# H5 register map
Vendor: Allwinner; Series: H5; File version: 0.1
CPU: 0, little endian, MPU, no FPU, 0 interrupt priority bits
Registers are 32-bit, read-write, reset 0x0 unless marked. A register's access mark holds for its fields unless they carry their own. Offsets are from the block's base; [hi:lo] are bit positions; {n}, {i} and the like mark numbered series.

## SPC
Base 0x01C23400
0x04 SPC_DECPORT0_STA_REG — SPC Decode Port0 Status Register
  [7:0] STA_DEC_PROT0_OUT ro — Shows the status of the decode protection output 0: Decode region corresponding to the bit is secure 1: Decode region corresponding to the bit is non-secure. There is one bit of the register for each protection output (See the SPC Configuration Table in Table 4-7 for detail).
{0x8+0xC*i} SPC_DECPORT{i}_SET_REG (i=0..2) — SPC Decode Port{i} Set Register
  [7:0] SET_DEC_PORT{i}_OUT wo — Sets the corresponding decode protection output. 0: No effect 1: Set decode region to non-secure. There is one bit of the register for each protection output (See the SPC Configuration Table in Table 4-7 for detail).
{0xC+0xC*i} SPC_DECPORT{i}_CLR_REG (i=0..2) — SPC Decode Port{i} Clear Register
  [7:0] CLR_DEC_PROT{i}_OUT wo — Clears the corresponding decode protection output. 0: No effect 1: Set decode region to secure. There is one bit of the register for each protection output (See the SPC Configuration Table in Table 4-7 for detail).
0x10 SPC_DECPORT1_STA_REG — SPC Decode Port1 Status Register
  [7:0] STA_DEC_PROT1_OUT ro — Shows the status of the decode protection output. 0: Decode region corresponding to the bit is secure 1: Decode region corresponding to the bit is non-secure. There is one bit of the register for each protection output (See the SPC Configuration Table in Table 4-7 for detail).
0x1C SPC_DECPORT2_STA_REG — SPC Decode Port2 Status Register
  [7:0] STA_DEC_PROT2_OUT ro — Show the status of the decode protection output. 0: Decode region corresponding to the bit is secure 1: Decode region corresponding to the bit is non-secure. There is one bit of the register for each protection output (See the SPC Configuration Table in Table 4-7 for detail).

## SPINLOCK
Base 0x01C18000
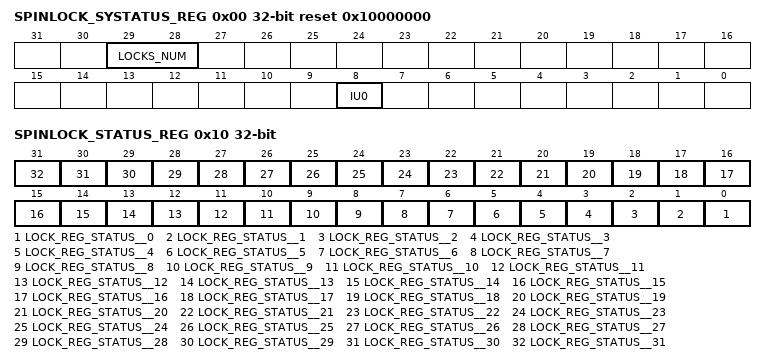
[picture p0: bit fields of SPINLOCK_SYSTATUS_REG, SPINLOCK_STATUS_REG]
0x00 SPINLOCK_SYSTATUS_REG reset 0x10000000 — Spinlock System Status Register
  [29:28] LOCKS_NUM ro — Number of lock registers implemented. 00: This instance has 32 lock registers. 01: This instance has 64 lock registers. 10: This instance has 128 lock registers. 11: This instance has 256 lock registers.
    0=This instance has 32 lock registers; 1=This instance has 64 lock registers; 2=This instance has 128 lock registers; 3=This instance has 256 lock registers
  [8] IU0 ro — In-Use flag0, covering lock register0-31. 0: All lock register 0-31 are in the NotTaken state. 1: At least one of the lock register 0-31 is in the Taken state.
    0=All (All lock register 0-31 are in the NotTaken state.); 1=At (At least one of the lock register 0-31 is in the Taken state.)
0x10 SPINLOCK_STATUS_REG — Spinlock Status Register
  [n] LOCK_REG_STATUS__{n} ro (n=0..31) — SpinLock[i] status (i=0~31) 0: The Spinlock is free 1: The Spinlock is taken.
{0x100+4i} SPINLOCKN_LOCK_REG[{i}] (i=0..31) — SPINLOCKN_LOCK_REG[{i}]
  [0] TAKEN — Lock State. Read 0x0: The lock was previously Not Taken (free).The requester is granted the lock. Write 0x0: Set the lock to Not Taken (free). Read 0x1: The lock was previously Taken. The requester is not granted the lock and must retry. Write 0x1: No update to the lock value.

## TWD
Base 0x01F01800
0x00 TWD_STATUS_REG — TWD Status Register
  [0] TWD_PEND_FLAG write-1-clears — Interrupt pending. Setting 1 to the bit will clear it. 0: No effect. 1: Pending.
    0=No_effect; 1=Pending
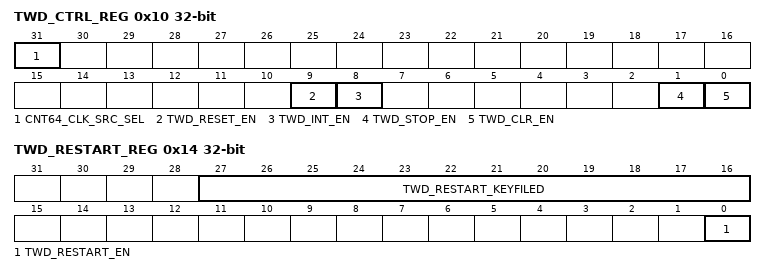
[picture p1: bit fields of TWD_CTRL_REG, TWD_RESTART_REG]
0x10 TWD_CTRL_REG — TWD Control Register
  [31] CNT64_CLK_SRC_SEL — 64-bit counter clock source select. 0: LOSC. 1: OSC24M.
    0=LOSC; 1=OSC24M
  [9] TWD_RESET_EN — TWD reset enable. 0: Reset disable. 1: Reset enable.
    0=Reset_disable; 1=Reset_enable
  [8] TWD_INT_EN — TWD Interrupt Enable. 0: Interrupt disable. 1: Interrupt enable.
    0=Interrupt_disable; 1=Interrupt_enable
  [1] TWD_STOP_EN — TWD stop enable. 0: Resume rolling-over. 1: Stop rolling-over.
    0=Resume rolling-over; 1=Stop rolling-over
  [0] TWD_CLR_EN — TWD clear enable. 0: No effect. 1: To clear relevant registers, it will change to zero after the registers are cleared.
    0=No_effect; 1=To clear relevant registers, it will change to zero after the registers are cleared
0x14 TWD_RESTART_REG — TWD Restart Register
  [27:16] TWD_RESTART_KEYFILED wo — It should be written to 0xD14. Writing any other value in this field aborts the write operation.
  [0] TWD_RESTART_EN wo — If writin g to this it, the alue of Counter Compare Registers would change. 0: No effect. 1: Restart enable.
    0=No_effect; 1=Restart enable
0x20 TWD_LOW_CNT_REG — TWD Low Counter Register
  [31:0] TWD_LOW_CNT ro — The TWD low 32-bit counter.
0x24 TWD_HIGH_CNT_REG — TWD High Counter Register
  [31:0] TWD_HIGH_CNT ro — The TWD high 32-bit counter.
0x30 TWD_INTV_VAL_REG — TWD Interval Value Register
  [31:0] TWD_INTV_VAL — The TWD interval value.
0x40 TWD_LOW_CNT_CMP_REG — TWD Low Counter Compare Register
  [31:0] TWD_LOW_CMP ro — The TWD low 32-bit compare counter.
0x44 TWD_HIGH_CNT_CMP_REG — TWD High Counter Compare Register
  [31:0] TWD_HIGH_CMP ro — The TWD high 32-bit compare counter.
0x100 SST_NV_CNT_REG — Secure Storage NV-Counter Register
  [31:0] SST_NV_CNT — This counter protects the trusted world secure storage file from replay attacks.
{0x110+4i} SYN_DATA_CNT_REG{i} (i=0..3) — Synchronize Data Counter Register {i}
  [31:0] SYN_DATA_CNT{i} — This counter is used for synchronizing data stores against replay attacks.

## Thermal_Sensor
Base 0x01C25000
0x00 THS_CTRL_REG0
  [15:0] SENSOR_ACQ — Sensor acquire time CLK_IN/(N+1)
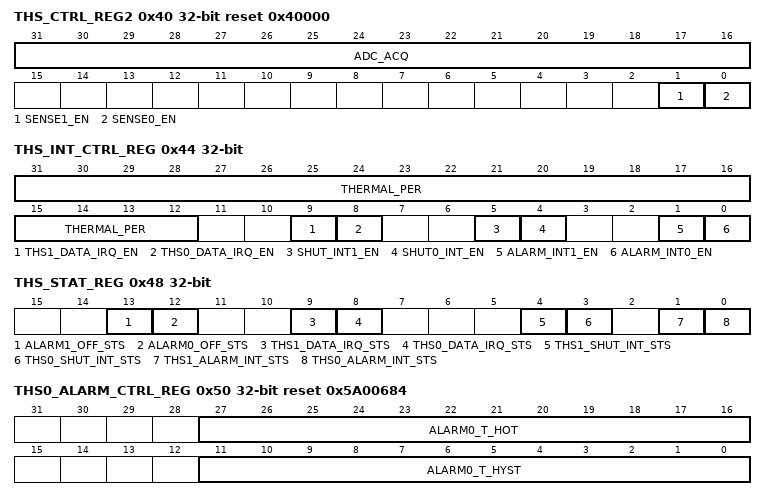
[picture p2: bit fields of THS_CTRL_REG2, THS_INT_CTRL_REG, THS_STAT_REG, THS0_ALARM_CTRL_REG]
0x40 THS_CTRL_REG2 reset 0x40000
  [31:16] ADC_ACQ — ADC acquire time CLK_IN/(N+1)
  [1] SENSE1_EN — Enable temperature measurement of sensor1 0:Disable 1:Enable
  [0] SENSE0_EN — Enable temperature measurement of sensor0 0:Disable 1:Enable
0x44 THS_INT_CTRL_REG
  [31:12] THERMAL_PER — 4096*(n+1)/CLK_IN
  [9] THS1_DATA_IRQ_EN — Enable temperature measurement data of sensor1 0: Disable 1: Enable
    0=Disable; 1=Enable
  [8] THS0_DATA_IRQ_EN — Enable temperature measurement data of sensor0 0: Disable 1: Enable
    0=Disable; 1=Enable
  [5] SHUT_INT1_EN — Enable shutdown interrupt of sensor1 0: Disable 1: Enable
    0=Disable; 1=Enable
  [4] SHUT0_INT_EN — Enable shutdown interrupt of sensor0 0: Disable 1: Enable
    0=Disable; 1=Enable
  [1] ALARM_INT1_EN — Enable alarm interrupt of sensor1 0: Disable 1: Enable
    0=Disable; 1=Enable
  [0] ALARM_INT0_EN — Enable alarm interrupt of sensor0 0: Disable 1: Enable
    0=Disable; 1=Enable
0x48 THS_STAT_REG
  [13] ALARM1_OFF_STS write-1-clears — Alarm interrupt off pending for sensor1 W ite to lea this i te upt o auto ati all lear if interrupt condition fails
  [12] ALARM0_OFF_STS write-1-clears — Alarm interrupt off pending for sensor0 W ite to lea this i te upt o auto ati all lea if i te upt o ditio fails
  [9] THS1_DATA_IRQ_STS write-1-clears — Data interrupt status for sensor1 W ite to lea this i te upt o auto ati all lea if i te upt o ditio fails
  [8] THS0_DATA_IRQ_STS write-1-clears — Data interrupt status for sensor0 W ite to lea this i te upt o auto ati all lea if i te upt o ditio n fails
  [4] THS1_SHUT_INT_STS write-1-clears — Shutdown interrupt status for sensor1 W ite to lea this i te upt o auto ati al ly clear if interrupt condition fails
  [3] THS0_SHUT_INT_STS write-1-clears — Shutdown interrupt status for sensor0 W ite to clear this interrupt or automatically clear if interrupt condition fails
  [1] THS1_ALARM_INT_STS write-1-clears — Alarm interrupt pending for sensor1 W ite to lea this i te upt o auto ati al ly clear if interrupt condition fails
  [0] THS0_ALARM_INT_STS write-1-clears — Alarm interrupt pending for sensor0 W ite to lea this i te upt o auto ati al ly clear if interrupt condition fails
0x50 THS0_ALARM_CTRL_REG reset 0x5A00684
  [27:16] ALARM0_T_HOT — Thermal sensor0 alarm threshold for hot temperature
  [11:0] ALARM0_T_HYST — Thermal sensor0 alarm threshold for hysteresis temperature
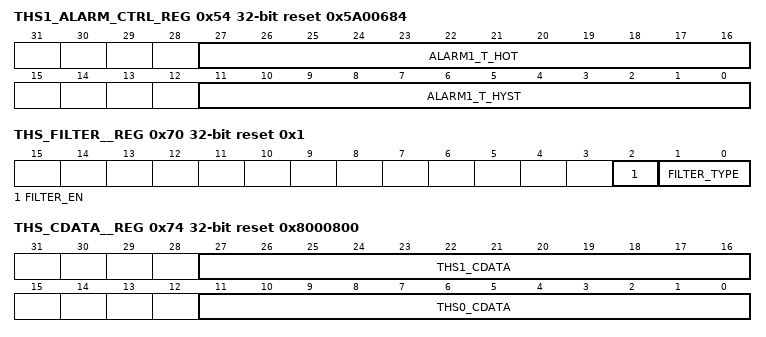
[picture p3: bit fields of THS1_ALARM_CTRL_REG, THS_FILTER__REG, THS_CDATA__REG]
0x54 THS1_ALARM_CTRL_REG reset 0x5A00684
  [27:16] ALARM1_T_HOT — Thermal sensor1 alarm threshold for hot temperature
  [11:0] ALARM1_T_HYST — Thermal sensor1 alarm threshold for hysteresis temperature
0x60 THS0_SHUTDOWN_CTRL_REG reset 0x4E90000
  [27:16] SHUT0_T_HOT — Thermal sensor0 shutdown threshold for hot temperature
0x64 THS1_SHUTDOWN_CTRL_REG reset 0x4E90000
  [27:16] SHUT1_T_HOT — Thermal sensor1 shutdown threshold for hot temperature
0x70 THS_FILTER__REG reset 0x1
  [2] FILTER_EN — Filter Enable 0: Disable 1: Enable
    0=Disable; 1=Enable
  [1:0] FILTER_TYPE — Average Filter Type 00: 2 01: 4 10: 8 11: 16
    0=_2; 1=_4; 2=_8; 3=_16
0x74 THS_CDATA__REG reset 0x8000800
  [27:16] THS1_CDATA — Thermal Sensor1 calibration data
  [11:0] THS0_CDATA — Thermal Sensor0 calibration data
0x80 THS0_DATA_REG
  [11:0] THS0_DATA ro — Temperature measurement data of sensor0
0x84 THS1_DATA_REG
  [11:0] THS1_DATA ro — Temperature measurement data of sensor1
